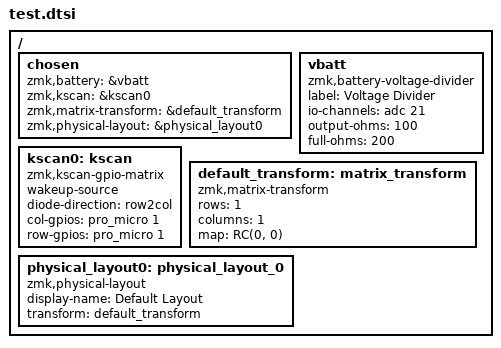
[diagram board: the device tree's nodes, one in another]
#include <dt-bindings/zmk/matrix_transform.h>

/ {
	chosen {
                zmk,battery = &vbatt;
		zmk,kscan = &kscan0;
		zmk,matrix-transform = &default_transform;
		zmk,physical-layout = &physical_layout0;
	};

        vbatt: vbatt {
            status = "okay";
            compatible = "zmk,battery-voltage-divider";
            label = "Voltage Divider";
            io-channels = <&adc 21>;
            output-ohms = <100>;
            full-ohms = <200>;

        };

        kscan0: kscan {
            compatible = "zmk,kscan-gpio-matrix";
            wakeup-source;

            diode-direction = "row2col";

            col-gpios
                = <&pro_micro 1 (GPIO_ACTIVE_HIGH | GPIO_PULL_DOWN)>
                ;

            row-gpios
                = <&pro_micro 1 GPIO_ACTIVE_HIGH>
                ;
        };

	default_transform: matrix_transform {
                compatible = "zmk,matrix-transform";
                rows = <1>;
                columns = <1>;

		map = < RC(0, 0) >;

	};

	physical_layout0: physical_layout_0 {
        compatible = "zmk,physical-layout";
        display-name = "Default Layout";
        transform = <&default_transform>;
    };
};
